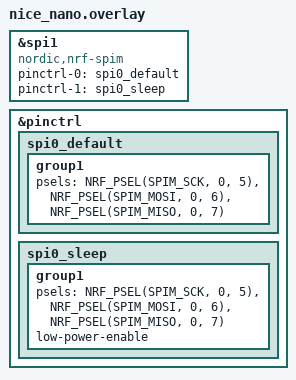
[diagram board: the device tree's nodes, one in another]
/*
 * Copyright (c) 2021 The ZMK Contributors
 *
 * SPDX-License-Identifier: MIT
 */

&spi1 {
    compatible = "nordic,nrf-spim";
    status = "okay";
    pinctrl-0 = <&spi0_default>;
    pinctrl-1 = <&spi0_sleep>;
    pinctrl-names = "default", "sleep";

};

&pinctrl {
	spi0_default: spi0_default {
		group1 {
			psels = <NRF_PSEL(SPIM_SCK, 0, 5)>,
				<NRF_PSEL(SPIM_MOSI, 0, 6)>,
				<NRF_PSEL(SPIM_MISO, 0, 7)>;
		};
	};

	spi0_sleep: spi0_sleep {
		group1 {
			psels = <NRF_PSEL(SPIM_SCK, 0, 5)>,
				<NRF_PSEL(SPIM_MOSI, 0, 6)>,
				<NRF_PSEL(SPIM_MISO, 0, 7)>;
			low-power-enable;
		};
	};
};
